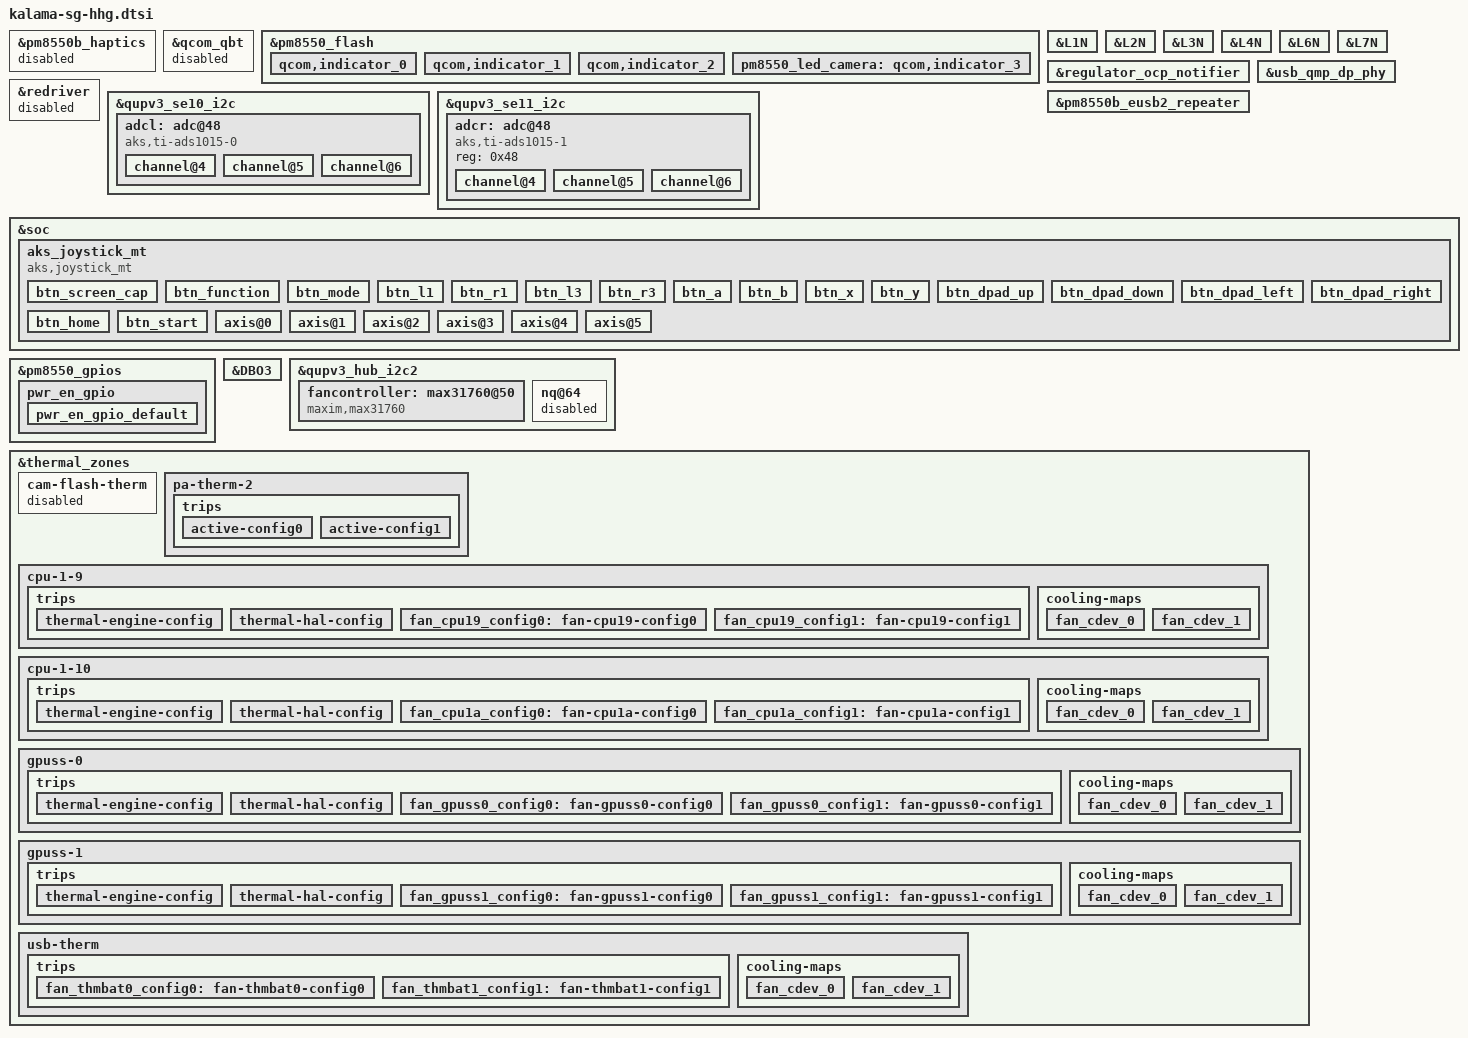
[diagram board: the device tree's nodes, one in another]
#include "kalama-qrd.dtsi"

&pm8550b_haptics {
	status = "disabled";
};

&qcom_qbt {
	status = "disabled";
};


&pm8550_flash {
	/delete-node/ qcom,flash_0;
	/delete-node/ qcom,flash_1;
	/delete-node/ qcom,flash_2;
	/delete-node/ qcom,flash_3;
	/delete-node/ qcom,torch_0;
	/delete-node/ qcom,torch_1;
	/delete-node/ qcom,torch_2;
	/delete-node/ qcom,torch_3;
	/delete-node/ qcom,led_switch_0;
	/delete-node/ qcom,led_switch_1;
	/delete-node/ qcom,led_switch_2;

	qcom,indicator_0 {
		label = "indicator";
		qcom,id = <0>;
		qcom,led-name = "led:white";
		qcom,max-current-ma = <20>;
		qcom,ires-ua = <5000>;
	};

	qcom,indicator_1 {
		label = "indicator";
		qcom,id = <1>;
		qcom,led-name = "led:blue";
		qcom,max-current-ma = <5>;
		qcom,ires-ua = <5000>;
	};

	qcom,indicator_2 {
		label = "indicator";
		qcom,id = <2>;
		qcom,led-name = "led:green";
		qcom,max-current-ma = <5>;
		qcom,ires-ua = <5000>;
	};

	pm8550_led_camera: qcom,indicator_3 {
		label = "indicator";
		qcom,id = <3>;
		qcom,led-name = "led:red";
		qcom,max-current-ma = <5>;
		qcom,ires-ua = <5000>;
		qcom,default-led-trigger = "front_camera";
	};
};

&L1N {
	regulator-max-microvolt = <1200000>;
	qcom,init-voltage = <1200000>;
};

&L2N {
	regulator-max-microvolt = <1200000>;
	qcom,init-voltage = <1200000>;
};

&L3N {
	regulator-max-microvolt = <3000000>;
	qcom,init-voltage = <3000000>;
};

&L4N {
	regulator-max-microvolt = <3300000>;
	qcom,init-voltage = <3300000>;
};

&L6N {
	regulator-min-microvolt = <2800000>;
	qcom,init-voltage = <2800000>;
};

&L7N {
	regulator-min-microvolt = <2800000>;
	qcom,init-voltage = <2800000>;
};

&regulator_ocp_notifier {
	/delete-property/ periph-c40-supply;
	/delete-property/ periph-c41-supply;
	/delete-property/ periph-c42-supply;
	/delete-property/ periph-c43-supply;
	/delete-property/ periph-c44-supply;
	/delete-property/ periph-c45-supply;
	/delete-property/ periph-c46-supply;
};

&usb_qmp_dp_phy {
	pinctrl-names = "default";
};

&redriver {
	status = "disabled";
};

&pm8550b_eusb2_repeater {
	qcom,param-override-seq =
		/* <value reg_offset> */
		/* Adjust HS trasmit amplitude */
		<0xd 0x51
		/* Squelch detection threshold */
		 0x3 0x54
		/* Tx pre-emphasis tuning */
		 0x7 0x57
		/* HS disconnect threshold */
		 0x6 0x53>;
};

&qupv3_se10_i2c {
	status = "ok";

	adcl: adc@48 {
		compatible = "aks,ti-ads1015-0";
		reg = <0x48>;
		ti,vdd-supply = <&L3N>;
		regulator-name = "ti,vdd";
		#address-cells = <1>;
		#size-cells = <0>;
		#io-channel-cells = <1>;

		channel@4 {
			reg = <4>;
			ti,gain = <2>;
			ti,datarate = <4>;
		};

		channel@5 {
			reg = <5>;
			ti,gain = <2>;
			ti,datarate = <4>;
		};

		channel@6 {
			reg = <6>;
			ti,gain = <1>;
			ti,datarate = <4>;
		};
	};
};

&qupv3_se11_i2c {
	status = "ok";

	adcr: adc@48 {
		compatible = "aks,ti-ads1015-1";
		reg = <0x48>;
		#address-cells = <1>;
		#size-cells = <0>;
		#io-channel-cells = <1>;

		channel@4 {
			reg = <4>;
			ti,gain = <2>;
			ti,datarate = <4>;
		};

		channel@5 {
			reg = <5>;
			ti,gain = <2>;
			ti,datarate = <4>;
		};

		channel@6 {
			reg = <6>;
			ti,gain = <1>;
			ti,datarate = <4>;
		};
	};
};

&soc {
	aks_joystick_mt: aks_joystick_mt {
		status = "ok";
		compatible = "aks,joystick_mt";
		label = "aks-joystick-mt";
		pinctrl-names = "default","sleep";
		pinctrl-0 = <&gpio_key_active>;
		pinctrl-1 = <&gpio_key_suspend>;
		io-channels = <&adcl 4>, <&adcl 5>, <&adcl 6>, <&adcr 4>, <&adcr 5>, <&adcr 6>;
		#address-cells = <1>;
		#size-cells = <0>;

		btn_screen_cap {
			label = "btn_screen_cap";
			gpios = <&tlmm 0 GPIO_ACTIVE_LOW>;
			linux,input-type = <1>;
			linux,code = <KEY_SYSRQ>;
			debounce-interval = <15>;
			linux,can-disable;
		};

		btn_function {
			label = "btn_function";
			gpios = <&tlmm 14 GPIO_ACTIVE_LOW>;
			linux,input-type = <1>;
			linux,code = <KEY_FN>;
			debounce-interval = <15>;
		};

		btn_mode {
			label = "btn_mode";
			gpios = <&tlmm 15 GPIO_ACTIVE_LOW>;
			linux,input-type = <1>;
			linux,code = <BTN_MODE>;
			debounce-interval = <15>;
		};

		btn_l1 {
			label = "btn_l1";
			gpios = <&tlmm 40 GPIO_ACTIVE_LOW>;
			linux,input-type = <1>;
			linux,code = <BTN_TL>;
			debounce-interval = <15>;
			linux,can-disable;
		};

		btn_r1 {
			label = "btn_r1";
			gpios = <&tlmm 48 GPIO_ACTIVE_LOW>;
			linux,input-type = <1>;
			linux,code = <BTN_TR>;
			debounce-interval = <15>;
			linux,can-disable;
		};

		btn_l3 {
			label = "btn_l3";
			gpios = <&tlmm 59 GPIO_ACTIVE_LOW>;
			linux,input-type = <1>;
			linux,code = <BTN_THUMBL>;
			debounce-interval = <15>;
			linux,can-disable;
		};

		btn_r3 {
			label = "btn_r3";
			gpios = <&tlmm 60 GPIO_ACTIVE_LOW>;
			linux,input-type = <1>;
			linux,code = <BTN_THUMBR>;
			debounce-interval = <15>;
			linux,can-disable;
		};

		btn_a {
			label = "btn_a";
			gpios = <&tlmm 89 GPIO_ACTIVE_LOW>;
			linux,input-type = <1>;
			linux,code = <BTN_A>;
			debounce-interval = <15>;
			linux,can-disable;
		};

		btn_b {
			label = "btn_b";
			gpios = <&tlmm 119 GPIO_ACTIVE_LOW>;
			linux,input-type = <1>;
			linux,code = <BTN_B>;
			debounce-interval = <15>;
			linux,can-disable;
		};

		btn_x {
			label = "btn_x";
			gpios = <&tlmm 56 GPIO_ACTIVE_LOW>;
			linux,input-type = <1>;
			linux,code = <BTN_X>;
			debounce-interval = <15>;
			linux,can-disable;
		};

		btn_y {
			label = "btn_y";
			gpios = <&tlmm 137 GPIO_ACTIVE_LOW>;
			linux,input-type = <1>;
			linux,code = <BTN_Y>;
			debounce-interval = <15>;
			linux,can-disable;
		};

		btn_dpad_up {
			label = "btn_dpad_up";
			gpios = <&tlmm 62 GPIO_ACTIVE_LOW>;
			linux,input-type = <1>;
			linux,code = <BTN_DPAD_UP>;
			debounce-interval = <15>;
			linux,can-disable;
		};

		btn_dpad_down {
			label = "btn_dpad_down";
			gpios = <&tlmm 63 GPIO_ACTIVE_LOW>;
			linux,input-type = <1>;
			linux,code = <BTN_DPAD_DOWN>;
			debounce-interval = <15>;
			linux,can-disable;
		};

		btn_dpad_left {
			label = "btn_dpad_left";
			gpios = <&tlmm 73 GPIO_ACTIVE_LOW>;
			linux,input-type = <1>;
			linux,code = <BTN_DPAD_LEFT>;
			debounce-interval = <15>;
			linux,can-disable;
		};

		btn_dpad_right {
			label = "btn_dpad_right";
			gpios = <&tlmm 75 GPIO_ACTIVE_LOW>;
			linux,input-type = <1>;
			linux,code = <BTN_DPAD_RIGHT>;
			debounce-interval = <15>;
			linux,can-disable;
		};

		btn_home {
			label = "btn_home";
			gpios = <&tlmm 85 GPIO_ACTIVE_LOW>;
			linux,input-type = <1>;
			linux,code = <KEY_HOME>;
			debounce-interval = <15>;
			linux,can-disable;
		};

		btn_start {
			label = "btn_start";
			gpios = <&tlmm 87 GPIO_ACTIVE_LOW>;
			linux,input-type = <1>;
			linux,code = <BTN_START>;
			debounce-interval = <15>;
			linux,can-disable;

		};

		axis@0 {
			reg = <0>;
			index = <0>;
			linux,code = <ABS_X>;
			abs-range = <580 2040>;
			abs-fuzz = <5>;
			abs-flat = <5>;
		};

		axis@1 {
			reg = <1>;
			index = <1>;
			linux,code = <ABS_Y>;
			abs-range = <630 2040>;
			abs-fuzz = <5>;
			abs-flat = <5>;
		};

		axis@2 {
			reg = <2>;
			index = <2>;
			linux,code = <ABS_BRAKE>;
			abs-range = <539 810>;
			abs-fuzz = <5>;
			abs-flat = <5>;
		};

		axis@3 {
			reg = <0>;
			index = <3>;
			linux,code = <ABS_Z>;
			abs-range = <580 2040>;
			abs-fuzz = <5>;
			abs-flat = <5>;
		};

		axis@4 {
			reg = <1>;
			index = <4>;
			linux,code = <ABS_RZ>;
			abs-range = <630 2040>;
			abs-fuzz = <5>;
			abs-flat = <5>;
		};

		axis@5 {
			reg = <2>;
			index = <5>;
			linux,code = <ABS_GAS>;
			abs-range = <539 810>;
			abs-fuzz = <5>;
			abs-flat = <5>;
		};
	};
};

&pm8550_gpios {
	pwr_en_gpio {
		pwr_en_gpio_default: pwr_en_gpio_default {
			pins = "gpio9";
			function = "normal";
			power-source = <0>;
			output-low;
			input-disable;
		};
	};

};

&DBO3 {
	/delete-property/ gpio;
};

&qupv3_hub_i2c2 {
	status = "ok";

	fancontroller: max31760@50 {
		compatible = "maxim,max31760";
		reg = <0x50>;
		#cooling-cells = <2>;
		maxim,fan-num = <1>;
		maxim,vdd-supply = <&L4N>;
		maxim,vcca-supply = <&L15B>;
		regulator-name = "maxim,vdd", "maxim,vcca";
		pinctrl-names = "default";
		pinctrl-0 = <&pwr_en_gpio_default>;
		maxim,pwr-en-gpio = <&pm8550_gpios 9 GPIO_ACTIVE_LOW>;
		status = "ok";
	};

	//disable FM
	nq@64 {
		status = "disabled";
	};
};

&thermal_zones {
	cam-flash-therm {
		status = "disabled";
	};

	pa-therm-2 {
		polling-delay-passive = <0>;
		polling-delay = <0>;
		thermal-sensors = <&pmk8550_vadc PM8550_ADC5_GEN3_AMUX_THM2_100K_PU>;
		trips {
			active-config0 {
				temperature = <125000>;
				hysteresis = <1000>;
				type = "passive";
			};

			active-config1 {
				temperature = <125000>;
				hysteresis = <1000>;
				type = "passive";
			};
		};
	};

	cpu-1-9 {
		trips {
			thermal-engine-config {
				temperature = <125000>;
				hysteresis = <1000>;
				type = "passive";
			};

			thermal-hal-config {
				temperature = <125000>;
				hysteresis = <1000>;
				type = "passive";
			};

			fan_cpu19_config0: fan-cpu19-config0 {
				temperature = <85000>;
				hysteresis = <0>;
				type = "passive";
			};

			fan_cpu19_config1: fan-cpu19-config1 {
				temperature = <90000>;
				hysteresis = <0>;
				type = "passive";
			};
		};

		cooling-maps {
			fan_cdev_0 {
				trip = <&fan_cpu19_config0>;
				cooling-device = <&fancontroller 50 50>;
			};

			fan_cdev_1 {
				trip = <&fan_cpu19_config1>;
				cooling-device = <&fancontroller 80 80>;
			};
		};
	};

	cpu-1-10 {
		trips {
			thermal-engine-config {
				temperature = <125000>;
				hysteresis = <1000>;
				type = "passive";
			};

			thermal-hal-config {
				temperature = <125000>;
				hysteresis = <1000>;
				type = "passive";
			};

			fan_cpu1a_config0: fan-cpu1a-config0 {
				temperature = <85000>;
				hysteresis = <0>;
				type = "passive";
			};

			fan_cpu1a_config1: fan-cpu1a-config1 {
				temperature = <90000>;
				hysteresis = <0>;
				type = "passive";
			};
		};

		cooling-maps {
			fan_cdev_0 {
				trip = <&fan_cpu1a_config0>;
				cooling-device = <&fancontroller 50 50>;
			};

			fan_cdev_1 {
				trip = <&fan_cpu1a_config1>;
				cooling-device = <&fancontroller 80 80>;
			};
		};
	};

	gpuss-0 {
		trips {
			thermal-engine-config {
				temperature = <125000>;
				hysteresis = <1000>;
				type = "passive";
			};

			thermal-hal-config {
				temperature = <125000>;
				hysteresis = <1000>;
				type = "passive";
			};

			fan_gpuss0_config0: fan-gpuss0-config0 {
				temperature = <70000>;
				hysteresis = <0>;
				type = "passive";
			};

			fan_gpuss0_config1: fan-gpuss0-config1 {
				temperature = <90000>;
				hysteresis = <0>;
				type = "passive";
			};
		};

		cooling-maps {
			fan_cdev_0 {
				trip = <&fan_gpuss0_config0>;
				cooling-device = <&fancontroller 80 80>;
			};

			fan_cdev_1 {
				trip = <&fan_gpuss0_config1>;
				cooling-device = <&fancontroller 100 100>;
			};
		};
	};

	gpuss-1 {
		trips {
			thermal-engine-config {
				temperature = <125000>;
				hysteresis = <1000>;
				type = "passive";
			};

			thermal-hal-config {
				temperature = <125000>;
				hysteresis = <1000>;
				type = "passive";
			};

			fan_gpuss1_config0: fan-gpuss1-config0 {
				temperature = <70000>;
				hysteresis = <0>;
				type = "passive";
			};

			fan_gpuss1_config1: fan-gpuss1-config1 {
				temperature = <90000>;
				hysteresis = <0>;
				type = "passive";
			};
		};

		cooling-maps {
			fan_cdev_0 {
				trip = <&fan_gpuss1_config0>;
				cooling-device = <&fancontroller 80 80>;
			};

			fan_cdev_1 {
				trip = <&fan_gpuss1_config1>;
				cooling-device = <&fancontroller 100 100>;
			};
		};
	};

	usb-therm {
		trips {
			fan_thmbat0_config0: fan-thmbat0-config0 {
				temperature = <43000>;
				hysteresis = <2000>;
				type = "passive";
			};

			fan_thmbat1_config1: fan-thmbat1-config1 {
				temperature = <45000>;
				hysteresis = <3000>;
				type = "passive";
			};
		};

		cooling-maps {
			fan_cdev_0 {
				trip = <&fan_thmbat0_config0>;
				cooling-device = <&fancontroller 80 80>;
			};

			fan_cdev_1 {
				trip = <&fan_thmbat1_config1>;
				cooling-device = <&fancontroller 100 100>;
			};
		};
	};
};
